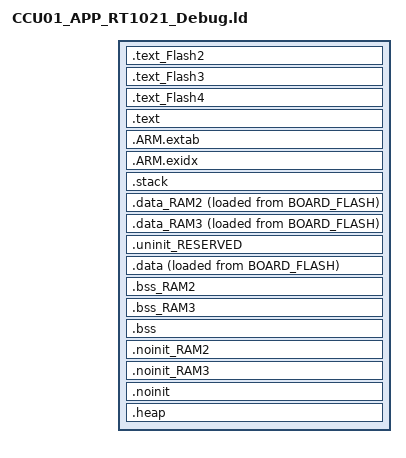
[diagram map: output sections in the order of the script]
/*
 * GENERATED FILE - DO NOT EDIT
 * Copyright 2008-2013 Code Red Technologies Ltd,
 * Copyright 2013-2025 NXP
 * Generated linker script file for MIMXRT1021xxxxx
 * Created from linkscript.ldt by FMCreateLinkLibraries
 * Using Freemarker v2.3.30
 * MCUXpresso IDE v11.10.0 [Build 3148] [2024-07-03] on 2025年11月27日 下午8:01:34
 */

INCLUDE "CCU01_APP_RT1021_Debug_library.ld"
INCLUDE "CCU01_APP_RT1021_Debug_memory.ld"

ENTRY(ResetISR)

SECTIONS
{
     .text_Flash2 : ALIGN(4)
    {
       FILL(0xff)
        *(.text_Flash2) /* for compatibility with previous releases */
        *(.text_APPINTEG) /* for compatibility with previous releases */
        *(.text.$Flash2)
        *(.text.$APPINTEG)
        *(.text_Flash2.*) /* for compatibility with previous releases */
        *(.text_APPINTEG.*) /* for compatibility with previous releases */
        *(.text.$Flash2.*)
        *(.text.$APPINTEG.*)
       *(app_integ_s)
        *(.rodata.$Flash2)
        *(.rodata.$APPINTEG)
        *(.rodata.$Flash2.*)
        *(.rodata.$APPINTEG.*)            } > APPINTEG

    .text_Flash3 : ALIGN(4)
    {
       FILL(0xff)
        *(.text_Flash3) /* for compatibility with previous releases */
        *(.text_APP_VERSION) /* for compatibility with previous releases */
        *(.text.$Flash3)
        *(.text.$APP_VERSION)
        *(.text_Flash3.*) /* for compatibility with previous releases */
        *(.text_APP_VERSION.*) /* for compatibility with previous releases */
        *(.text.$Flash3.*)
        *(.text.$APP_VERSION.*)
       *(app_ver_s)
        *(.rodata.$Flash3)
        *(.rodata.$APP_VERSION)
        *(.rodata.$Flash3.*)
        *(.rodata.$APP_VERSION.*)            } > APP_VERSION

    .text_Flash4 : ALIGN(4)
    {
       FILL(0xff)
        *(.text_Flash4) /* for compatibility with previous releases */
        *(.text_BOOT_VERSION) /* for compatibility with previous releases */
        *(.text.$Flash4)
        *(.text.$BOOT_VERSION)
        *(.text_Flash4.*) /* for compatibility with previous releases */
        *(.text_BOOT_VERSION.*) /* for compatibility with previous releases */
        *(.text.$Flash4.*)
        *(.text.$BOOT_VERSION.*)
       *(boot_ver_s)
        *(.rodata.$Flash4)
        *(.rodata.$BOOT_VERSION)
        *(.rodata.$Flash4.*)
        *(.rodata.$BOOT_VERSION.*)            } > BOOT_VERSION

    /* MAIN TEXT SECTION */
    .text : ALIGN(4)
    {
        FILL(0xff)
        __vectors_start__ = ABSOLUTE(.) ;
        KEEP(*(.isr_vector))
        /* Global Section Table */
        . = ALIGN(4) ;
        __section_table_start = .;
        __data_section_table = .;
        LONG(LOADADDR(.data));
        LONG(    ADDR(.data));
        LONG(  SIZEOF(.data));
        LONG(LOADADDR(.data_RAM2));
        LONG(    ADDR(.data_RAM2));
        LONG(  SIZEOF(.data_RAM2));
        LONG(LOADADDR(.data_RAM3));
        LONG(    ADDR(.data_RAM3));
        LONG(  SIZEOF(.data_RAM3));
        __data_section_table_end = .;
        __bss_section_table = .;
        LONG(    ADDR(.bss));
        LONG(  SIZEOF(.bss));
        LONG(    ADDR(.bss_RAM2));
        LONG(  SIZEOF(.bss_RAM2));
        LONG(    ADDR(.bss_RAM3));
        LONG(  SIZEOF(.bss_RAM3));
        __bss_section_table_end = .;
        __section_table_end = . ;
        /* End of Global Section Table */

        *(.after_vectors*)

       *(.text*)
       KEEP(*freertos*/tasks.o(.rodata*)) /* FreeRTOS Debug Config */
       *(.rodata .rodata.* .constdata .constdata.*)
       . = ALIGN(4);
    } > BOARD_FLASH
    /*
     * for exception handling/unwind - some Newlib functions (in common
     * with C++ and STDC++) use this.
     */
    .ARM.extab : ALIGN(4)
    {
        *(.ARM.extab* .gnu.linkonce.armextab.*)
    } > BOARD_FLASH

    .ARM.exidx : ALIGN(4)
    {
        __exidx_start = .;
        *(.ARM.exidx* .gnu.linkonce.armexidx.*)
        __exidx_end = .;
    } > BOARD_FLASH
 
    _etext = .;
        

    /* Reserve and place Stack within memory map */
    _StackSize = 0x400;
    .stack (NOLOAD) :  ALIGN(4)
    {
        _vStackBase = .;
        . += _StackSize;
        . = ALIGN(4);
        _vStackTop = .;
    } > SRAM_DTC
    /* DATA section for SRAM_ITC */

    .data_RAM2 : ALIGN(4)
    {
        FILL(0xff)
        PROVIDE(__start_data_RAM2 = .) ;
        PROVIDE(__start_data_SRAM_ITC = .) ;
        *(.ramfunc.$RAM2)
        *(.ramfunc.$SRAM_ITC)
        *(.data.$RAM2)
        *(.data.$SRAM_ITC)
        *(.data.$RAM2.*)
        *(.data.$SRAM_ITC.*)
        . = ALIGN(4) ;
        PROVIDE(__end_data_RAM2 = .) ;
        PROVIDE(__end_data_SRAM_ITC = .) ;
     } > SRAM_ITC AT>BOARD_FLASH

    /* DATA section for SRAM_OC */

    .data_RAM3 : ALIGN(4)
    {
        FILL(0xff)
        PROVIDE(__start_data_RAM3 = .) ;
        PROVIDE(__start_data_SRAM_OC = .) ;
        *(.ramfunc.$RAM3)
        *(.ramfunc.$SRAM_OC)
        *(.data.$RAM3)
        *(.data.$SRAM_OC)
        *(.data.$RAM3.*)
        *(.data.$SRAM_OC.*)
        . = ALIGN(4) ;
        PROVIDE(__end_data_RAM3 = .) ;
        PROVIDE(__end_data_SRAM_OC = .) ;
     } > SRAM_OC AT>BOARD_FLASH

    /* MAIN DATA SECTION */
    .uninit_RESERVED (NOLOAD) : ALIGN(4)
    {
        _start_uninit_RESERVED = .;
        KEEP(*(.bss.$RESERVED*))
       . = ALIGN(4) ;
        _end_uninit_RESERVED = .;
    } > SRAM_DTC AT> SRAM_DTC

    /* Main DATA section (SRAM_DTC) */
    .data : ALIGN(4)
    {
       FILL(0xff)
       _data = . ;
       PROVIDE(__start_data_RAM = .) ;
       PROVIDE(__start_data_SRAM_DTC = .) ;
       *(vtable)
       *(.ramfunc*)
       KEEP(*(CodeQuickAccess))
       KEEP(*(DataQuickAccess))
       *(RamFunction)
       *(NonCacheable.init)
       *(.data*)
       . = ALIGN(4) ;
       _edata = . ;
       PROVIDE(__end_data_RAM = .) ;
       PROVIDE(__end_data_SRAM_DTC = .) ;
    } > SRAM_DTC AT>BOARD_FLASH

    /* BSS section for SRAM_ITC */
    .bss_RAM2 (NOLOAD) : ALIGN(4)
    {
       PROVIDE(__start_bss_RAM2 = .) ;
       PROVIDE(__start_bss_SRAM_ITC = .) ;
       *(.bss.$RAM2)
       *(.bss.$SRAM_ITC)
       *(.bss.$RAM2.*)
       *(.bss.$SRAM_ITC.*)
       . = ALIGN (. != 0 ? 4 : 1) ; /* avoid empty segment */
       PROVIDE(__end_bss_RAM2 = .) ;
       PROVIDE(__end_bss_SRAM_ITC = .) ;
    } > SRAM_ITC AT> SRAM_ITC

    /* BSS section for SRAM_OC */
    .bss_RAM3 (NOLOAD) : ALIGN(4)
    {
       PROVIDE(__start_bss_RAM3 = .) ;
       PROVIDE(__start_bss_SRAM_OC = .) ;
       *(.bss.$RAM3)
       *(.bss.$SRAM_OC)
       *(.bss.$RAM3.*)
       *(.bss.$SRAM_OC.*)
       . = ALIGN (. != 0 ? 4 : 1) ; /* avoid empty segment */
       PROVIDE(__end_bss_RAM3 = .) ;
       PROVIDE(__end_bss_SRAM_OC = .) ;
    } > SRAM_OC AT> SRAM_OC

    /* MAIN BSS SECTION */
    .bss (NOLOAD) : ALIGN(4)
    {
        _bss = .;
        PROVIDE(__start_bss_RAM = .) ;
        PROVIDE(__start_bss_SRAM_DTC = .) ;
       *(NonCacheable)
        *(.bss*)
        *(COMMON)
        . = ALIGN(4) ;
        _ebss = .;
        PROVIDE(__end_bss_RAM = .) ;
        PROVIDE(__end_bss_SRAM_DTC = .) ;
        PROVIDE(end = .);
    } > SRAM_DTC AT> SRAM_DTC

    /* NOINIT section for SRAM_ITC */
    .noinit_RAM2 (NOLOAD) : ALIGN(4)
    {
       PROVIDE(__start_noinit_RAM2 = .) ;
       PROVIDE(__start_noinit_SRAM_ITC = .) ;
       *(.noinit.$RAM2)
       *(.noinit.$SRAM_ITC)
       *(.noinit.$RAM2.*)
       *(.noinit.$SRAM_ITC.*)
       . = ALIGN(4) ;
       PROVIDE(__end_noinit_RAM2 = .) ;
       PROVIDE(__end_noinit_SRAM_ITC = .) ;
    } > SRAM_ITC AT> SRAM_ITC

    /* NOINIT section for SRAM_OC */
    .noinit_RAM3 (NOLOAD) : ALIGN(4)
    {
       PROVIDE(__start_noinit_RAM3 = .) ;
       PROVIDE(__start_noinit_SRAM_OC = .) ;
       *(.noinit.$RAM3)
       *(.noinit.$SRAM_OC)
       *(.noinit.$RAM3.*)
       *(.noinit.$SRAM_OC.*)
       . = ALIGN(4) ;
       PROVIDE(__end_noinit_RAM3 = .) ;
       PROVIDE(__end_noinit_SRAM_OC = .) ;
    } > SRAM_OC AT> SRAM_OC

    /* DEFAULT NOINIT SECTION */
    .noinit (NOLOAD): ALIGN(4)
    {
        _noinit = .;
        PROVIDE(__start_noinit_RAM = .) ;
        PROVIDE(__start_noinit_SRAM_DTC = .) ;
        *(.noinit*)
         . = ALIGN(4) ;
        _end_noinit = .;
       PROVIDE(__end_noinit_RAM = .) ;
       PROVIDE(__end_noinit_SRAM_DTC = .) ;        
    } > SRAM_DTC AT> SRAM_DTC

    /* Reserve and place Heap within memory map */
    _HeapSize = 0x400;
    .heap (NOLOAD) :  ALIGN(4)
    {
        _pvHeapStart = .;
        . += _HeapSize;
        . = ALIGN(4);
        _pvHeapLimit = .;
    } > SRAM_DTC

    /* Provide basic symbols giving location and size of main text
     * block, including initial values of RW data sections. Note that
     * these will need extending to give a complete picture with
     * complex images (e.g multiple Flash banks).
     */
    _image_start = LOADADDR(.text);
    _image_end = LOADADDR(.data) + SIZEOF(.data);
    _image_size = _image_end - _image_start;
}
